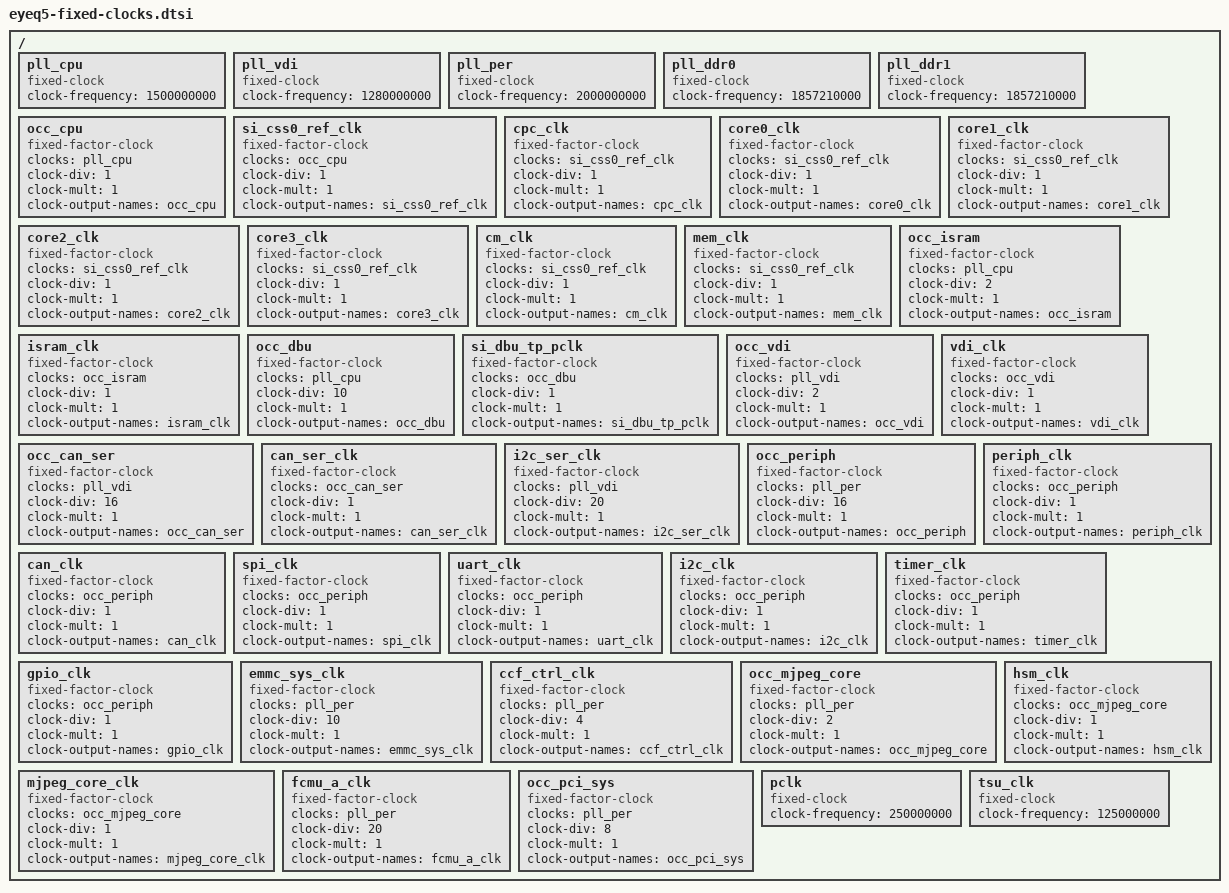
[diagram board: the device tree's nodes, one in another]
// SPDX-License-Identifier: (GPL-2.0-only OR BSD-2-Clause)
/*
 * Copyright 2023 Mobileye Vision Technologies Ltd.
 */

/ {
	/* Fixed clock */
	pll_cpu: pll_cpu {
		compatible = "fixed-clock";
		#clock-cells = <0>;
		clock-frequency = <1500000000>;
	};

	pll_vdi: pll_vdi {
		compatible = "fixed-clock";
		#clock-cells = <0>;
		clock-frequency = <1280000000>;
	};

	pll_per: pll_per {
		compatible = "fixed-clock";
		#clock-cells = <0>;
		clock-frequency = <2000000000>;
	};

	pll_ddr0: pll_ddr0 {
		compatible = "fixed-clock";
		#clock-cells = <0>;
		clock-frequency = <1857210000>;
	};

	pll_ddr1: pll_ddr1 {
		compatible = "fixed-clock";
		#clock-cells = <0>;
		clock-frequency = <1857210000>;
	};

/* PLL_CPU derivatives */
	occ_cpu: occ_cpu {
		compatible = "fixed-factor-clock";
		clocks = <&pll_cpu>;
		#clock-cells = <0>;
		clock-div = <1>;
		clock-mult = <1>;
		clock-output-names = "occ_cpu";
	};
	si_css0_ref_clk: si_css0_ref_clk { /* gate ClkRstGen_si_css0_ref */
		compatible = "fixed-factor-clock";
		clocks = <&occ_cpu>;
		#clock-cells = <0>;
		clock-div = <1>;
		clock-mult = <1>;
		clock-output-names = "si_css0_ref_clk";
	};
	cpc_clk: cpc_clk {
		compatible = "fixed-factor-clock";
		clocks = <&si_css0_ref_clk>;
		#clock-cells = <0>;
		clock-div = <1>;
		clock-mult = <1>;
		clock-output-names = "cpc_clk";
	};
	core0_clk: core0_clk {
		compatible = "fixed-factor-clock";
		clocks = <&si_css0_ref_clk>;
		#clock-cells = <0>;
		clock-div = <1>;
		clock-mult = <1>;
		clock-output-names = "core0_clk";
	};
	core1_clk: core1_clk {
		compatible = "fixed-factor-clock";
		clocks = <&si_css0_ref_clk>;
		#clock-cells = <0>;
		clock-div = <1>;
		clock-mult = <1>;
		clock-output-names = "core1_clk";
	};
	core2_clk: core2_clk {
		compatible = "fixed-factor-clock";
		clocks = <&si_css0_ref_clk>;
		#clock-cells = <0>;
		clock-div = <1>;
		clock-mult = <1>;
		clock-output-names = "core2_clk";
	};
	core3_clk: core3_clk {
		compatible = "fixed-factor-clock";
		clocks = <&si_css0_ref_clk>;
		#clock-cells = <0>;
		clock-div = <1>;
		clock-mult = <1>;
		clock-output-names = "core3_clk";
	};
	cm_clk: cm_clk {
		compatible = "fixed-factor-clock";
		clocks = <&si_css0_ref_clk>;
		#clock-cells = <0>;
		clock-div = <1>;
		clock-mult = <1>;
		clock-output-names = "cm_clk";
	};
	mem_clk: mem_clk {
		compatible = "fixed-factor-clock";
		clocks = <&si_css0_ref_clk>;
		#clock-cells = <0>;
		clock-div = <1>;
		clock-mult = <1>;
		clock-output-names = "mem_clk";
	};
	occ_isram: occ_isram {
		compatible = "fixed-factor-clock";
		clocks = <&pll_cpu>;
		#clock-cells = <0>;
		clock-div = <2>;
		clock-mult = <1>;
		clock-output-names = "occ_isram";
	};
	isram_clk: isram_clk { /* gate ClkRstGen_isram */
		compatible = "fixed-factor-clock";
		clocks = <&occ_isram>;
		#clock-cells = <0>;
		clock-div = <1>;
		clock-mult = <1>;
		clock-output-names = "isram_clk";
	};
	occ_dbu: occ_dbu {
		compatible = "fixed-factor-clock";
		clocks = <&pll_cpu>;
		#clock-cells = <0>;
		clock-div = <10>;
		clock-mult = <1>;
		clock-output-names = "occ_dbu";
	};
	si_dbu_tp_pclk: si_dbu_tp_pclk { /* gate ClkRstGen_dbu */
		compatible = "fixed-factor-clock";
		clocks = <&occ_dbu>;
		#clock-cells = <0>;
		clock-div = <1>;
		clock-mult = <1>;
		clock-output-names = "si_dbu_tp_pclk";
	};
/* PLL_VDI derivatives */
	occ_vdi: occ_vdi {
		compatible = "fixed-factor-clock";
		clocks = <&pll_vdi>;
		#clock-cells = <0>;
		clock-div = <2>;
		clock-mult = <1>;
		clock-output-names = "occ_vdi";
	};
	vdi_clk: vdi_clk { /* gate ClkRstGen_vdi */
		compatible = "fixed-factor-clock";
		clocks = <&occ_vdi>;
		#clock-cells = <0>;
		clock-div = <1>;
		clock-mult = <1>;
		clock-output-names = "vdi_clk";
	};
	occ_can_ser: occ_can_ser {
		compatible = "fixed-factor-clock";
		clocks = <&pll_vdi>;
		#clock-cells = <0>;
		clock-div = <16>;
		clock-mult = <1>;
		clock-output-names = "occ_can_ser";
	};
	can_ser_clk: can_ser_clk { /* gate ClkRstGen_can_ser */
		compatible = "fixed-factor-clock";
		clocks = <&occ_can_ser>;
		#clock-cells = <0>;
		clock-div = <1>;
		clock-mult = <1>;
		clock-output-names = "can_ser_clk";
	};
	i2c_ser_clk: i2c_ser_clk {
		compatible = "fixed-factor-clock";
		clocks = <&pll_vdi>;
		#clock-cells = <0>;
		clock-div = <20>;
		clock-mult = <1>;
		clock-output-names = "i2c_ser_clk";
	};
/* PLL_PER derivatives */
	occ_periph: occ_periph {
		compatible = "fixed-factor-clock";
		clocks = <&pll_per>;
		#clock-cells = <0>;
		clock-div = <16>;
		clock-mult = <1>;
		clock-output-names = "occ_periph";
	};
	periph_clk: periph_clk {
		compatible = "fixed-factor-clock";
		clocks = <&occ_periph>;
		#clock-cells = <0>;
		clock-div = <1>;
		clock-mult = <1>;
		clock-output-names = "periph_clk";
	};
	can_clk: can_clk {
		compatible = "fixed-factor-clock";
		clocks = <&occ_periph>;
		#clock-cells = <0>;
		clock-div = <1>;
		clock-mult = <1>;
		clock-output-names = "can_clk";
	};
	spi_clk: spi_clk {
		compatible = "fixed-factor-clock";
		clocks = <&occ_periph>;
		#clock-cells = <0>;
		clock-div = <1>;
		clock-mult = <1>;
		clock-output-names = "spi_clk";
	};
	uart_clk: uart_clk {
		compatible = "fixed-factor-clock";
		clocks = <&occ_periph>;
		#clock-cells = <0>;
		clock-div = <1>;
		clock-mult = <1>;
		clock-output-names = "uart_clk";
	};
	i2c_clk: i2c_clk {
		compatible = "fixed-factor-clock";
		clocks = <&occ_periph>;
		#clock-cells = <0>;
		clock-div = <1>;
		clock-mult = <1>;
		clock-output-names = "i2c_clk";
	};
	timer_clk: timer_clk {
		compatible = "fixed-factor-clock";
		clocks = <&occ_periph>;
		#clock-cells = <0>;
		clock-div = <1>;
		clock-mult = <1>;
		clock-output-names = "timer_clk";
	};
	gpio_clk: gpio_clk {
		compatible = "fixed-factor-clock";
		clocks = <&occ_periph>;
		#clock-cells = <0>;
		clock-div = <1>;
		clock-mult = <1>;
		clock-output-names = "gpio_clk";
	};
	emmc_sys_clk: emmc_sys_clk {
		compatible = "fixed-factor-clock";
		clocks = <&pll_per>;
		#clock-cells = <0>;
		clock-div = <10>;
		clock-mult = <1>;
		clock-output-names = "emmc_sys_clk";
	};
	ccf_ctrl_clk: ccf_ctrl_clk {
		compatible = "fixed-factor-clock";
		clocks = <&pll_per>;
		#clock-cells = <0>;
		clock-div = <4>;
		clock-mult = <1>;
		clock-output-names = "ccf_ctrl_clk";
	};
	occ_mjpeg_core: occ_mjpeg_core {
		compatible = "fixed-factor-clock";
		clocks = <&pll_per>;
		#clock-cells = <0>;
		clock-div = <2>;
		clock-mult = <1>;
		clock-output-names = "occ_mjpeg_core";
	};
	hsm_clk: hsm_clk { /* gate ClkRstGen_hsm */
		compatible = "fixed-factor-clock";
		clocks = <&occ_mjpeg_core>;
		#clock-cells = <0>;
		clock-div = <1>;
		clock-mult = <1>;
		clock-output-names = "hsm_clk";
	};
	mjpeg_core_clk: mjpeg_core_clk { /* gate ClkRstGen_mjpeg_gen */
		compatible = "fixed-factor-clock";
		clocks = <&occ_mjpeg_core>;
		#clock-cells = <0>;
		clock-div = <1>;
		clock-mult = <1>;
		clock-output-names = "mjpeg_core_clk";
	};
	fcmu_a_clk: fcmu_a_clk {
		compatible = "fixed-factor-clock";
		clocks = <&pll_per>;
		#clock-cells = <0>;
		clock-div = <20>;
		clock-mult = <1>;
		clock-output-names = "fcmu_a_clk";
	};
	occ_pci_sys: occ_pci_sys {
		compatible = "fixed-factor-clock";
		clocks = <&pll_per>;
		#clock-cells = <0>;
		clock-div = <8>;
		clock-mult = <1>;
		clock-output-names = "occ_pci_sys";
	};
	pclk: pclk {
		compatible = "fixed-clock";
		#clock-cells = <0>;
		clock-frequency = <250000000>;  /* 250MHz */
	};
	tsu_clk: tsu_clk {
		compatible = "fixed-clock";
		#clock-cells = <0>;
		clock-frequency = <125000000>;  /* 125MHz */
	};
};
